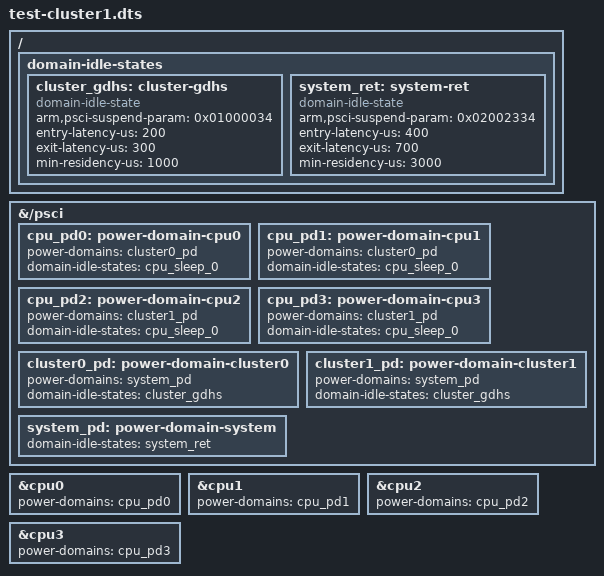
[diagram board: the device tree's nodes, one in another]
// SPDX-License-Identifier: BSD-3-Clause
/*
 * CPU idle test, stage 3: cluster idle with the hierarchical PSCI layout.
 * Needs a kernel with CONFIG_ARM_PSCI_CPUIDLE(_DOMAIN)=y.
 *
 * Each CPU gets a PSCI power domain with the accepted CPU state (0x4, see
 * test-idle2.dts for why not 0x40000004), parented to a cluster domain
 * (CPU0-1, CPU2-3). Linux then uses OSI mode: when the last CPU of a
 * cluster goes idle it requests the cluster state, whose parameter is the
 * whole composite StateID.
 *
 * Stock (msm8996-pm.dtsi) composes: power-down bit 30, affinity level at
 * bit 24, cluster mode at bit 4 (1 L2 WFI, 3 L2 GDHS, 4 L2 power collapse),
 * CPU mode at bit 0. Stock only enters cluster modes with the CPUs in their
 * power-down level (0x41000034 for GDHS). That bit is refused here, so try
 * GDHS without it: 0x01000034.
 *
 * The firmware is OSI from boot but answers NOT_SUPPORTED to
 * SET_SUSPEND_MODE, so this needs the cpuidle-psci-domain quirk that treats
 * that answer as "already OSI" on msm8996/apq8096.
 *
 * Probing with flat states (test-cluster2/3.dts) showed which composite
 * StateIDs it grants when the caller is the last CPU: 0x01000034 (L2 GDHS)
 * and 0x02002334 (system retention: affinity level 2, system mode 0x23 at
 * bit 8). L2 power collapse (0x41000044) is always DENIED, as it needs the
 * CPUs in their power-down state. So: CPU -> cluster (GDHS) -> system
 * (retention). The parameter of the highest domain going down is the whole
 * StateID. Latencies are conservative; stock lists 90 and 350 us.
 */

#include "test-charger.dts"

/ {
	domain-idle-states {
		cluster_gdhs: cluster-gdhs {
			compatible = "domain-idle-state";
			arm,psci-suspend-param = <0x01000034>;
			entry-latency-us = <200>;
			exit-latency-us = <300>;
			min-residency-us = <1000>;
		};

		system_ret: system-ret {
			compatible = "domain-idle-state";
			arm,psci-suspend-param = <0x02002334>;
			entry-latency-us = <400>;
			exit-latency-us = <700>;
			min-residency-us = <3000>;
		};
	};
};

&{/psci} {
	cpu_pd0: power-domain-cpu0 {
		#power-domain-cells = <0>;
		power-domains = <&cluster0_pd>;
		domain-idle-states = <&cpu_sleep_0>;
	};

	cpu_pd1: power-domain-cpu1 {
		#power-domain-cells = <0>;
		power-domains = <&cluster0_pd>;
		domain-idle-states = <&cpu_sleep_0>;
	};

	cpu_pd2: power-domain-cpu2 {
		#power-domain-cells = <0>;
		power-domains = <&cluster1_pd>;
		domain-idle-states = <&cpu_sleep_0>;
	};

	cpu_pd3: power-domain-cpu3 {
		#power-domain-cells = <0>;
		power-domains = <&cluster1_pd>;
		domain-idle-states = <&cpu_sleep_0>;
	};

	cluster0_pd: power-domain-cluster0 {
		#power-domain-cells = <0>;
		power-domains = <&system_pd>;
		domain-idle-states = <&cluster_gdhs>;
	};

	cluster1_pd: power-domain-cluster1 {
		#power-domain-cells = <0>;
		power-domains = <&system_pd>;
		domain-idle-states = <&cluster_gdhs>;
	};

	system_pd: power-domain-system {
		#power-domain-cells = <0>;
		domain-idle-states = <&system_ret>;
	};
};

&cpu0 {
	/delete-property/ cpu-idle-states;
	power-domains = <&cpu_pd0>;
	power-domain-names = "psci";
};

&cpu1 {
	/delete-property/ cpu-idle-states;
	power-domains = <&cpu_pd1>;
	power-domain-names = "psci";
};

&cpu2 {
	/delete-property/ cpu-idle-states;
	power-domains = <&cpu_pd2>;
	power-domain-names = "psci";
};

&cpu3 {
	/delete-property/ cpu-idle-states;
	power-domains = <&cpu_pd3>;
	power-domain-names = "psci";
};
